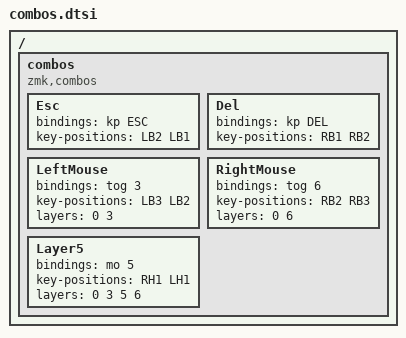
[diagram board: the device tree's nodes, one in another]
/ {
    combos {
        compatible = "zmk,combos";

        Esc {
            bindings = <&kp ESC>;
            key-positions = <LB2 LB1>;
        };

        Del {
            bindings = <&kp DEL>;
            key-positions = <RB1 RB2>;
        };

        LeftMouse {
            bindings = <&tog 3>;
            key-positions = <LB3 LB2>;
            layers = <0 3>;
        };

        RightMouse {
            bindings = <&tog 6>;
            key-positions = <RB2 RB3>;
            layers = <0 6>;
        };

        Layer5 {
            bindings = <&mo 5>;
            key-positions = <RH1 LH1>;
            layers = <0 3 5 6>;
        };
    };
};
